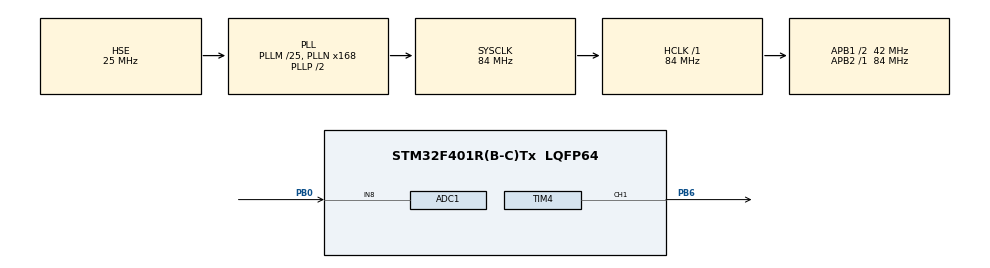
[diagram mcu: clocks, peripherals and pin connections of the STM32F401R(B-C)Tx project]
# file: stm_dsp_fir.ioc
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ADC1.Channel-4\#ChannelRegularConversion=ADC_CHANNEL_8
ADC1.ContinuousConvMode=DISABLE
ADC1.ExternalTrigConv=ADC_EXTERNALTRIGCONV_T2_TRGO
ADC1.NbrOfConversion=1
ADC1.NbrOfConversionFlag=1
ADC1.Rank-4\#ChannelRegularConversion=1
ADC1.Resolution=ADC_RESOLUTION_8B
ADC1.SamplingTime-4\#ChannelRegularConversion=ADC_SAMPLETIME_3CYCLES
ADC1.master=1
Mcu.Family=STM32F4
Mcu.Name=STM32F401R(B-C)Tx
Mcu.Package=LQFP64
NVIC.ADC_IRQn=true\:0\:0\:false\:false\:true\:true\:true\:true
NVIC.PriorityGroup=NVIC_PRIORITYGROUP_4
NVIC.TIM3_IRQn=true\:0\:0\:false\:false\:true\:true\:true\:true
PB0.Signal=ADCx_IN8
PB6.Signal=S_TIM4_CH1
PH0\ -\ OSC_IN.Mode=HSE-External-Oscillator
PH0\ -\ OSC_IN.Signal=RCC_OSC_IN
PH1\ -\ OSC_OUT.Mode=HSE-External-Oscillator
PH1\ -\ OSC_OUT.Signal=RCC_OSC_OUT
ProjectManager.HeapSize=0x200
ProjectManager.StackSize=0x400
ProjectManager.TargetToolchain=STM32CubeIDE
RCC.48MHZClocksFreq_Value=42000000
RCC.AHBFreq_Value=84000000
RCC.APB1CLKDivider=RCC_HCLK_DIV2
RCC.APB1Freq_Value=42000000
RCC.APB1TimFreq_Value=84000000
RCC.APB2Freq_Value=84000000
RCC.APB2TimFreq_Value=84000000
RCC.CortexFreq_Value=84000000
RCC.HCLKFreq_Value=84000000
RCC.HSE_VALUE=25000000
RCC.HSI_VALUE=16000000
RCC.LSE_VALUE=32768
RCC.PLLM=25
RCC.PLLN=168
RCC.PLLSourceVirtual=RCC_PLLSOURCE_HSE
RCC.SYSCLKFreq_VALUE=84000000
RCC.SYSCLKSource=RCC_SYSCLKSOURCE_PLLCLK
RCC.VCOOutputFreq_Value=168000000
SH.ADCx_IN8.0=ADC1_IN8,IN8
SH.S_TIM4_CH1.0=TIM4_CH1,PWM Generation1 CH1
TIM2.AutoReloadPreload=TIM_AUTORELOAD_PRELOAD_ENABLE
TIM2.Period=83999
TIM2.TIM_MasterOutputTrigger=TIM_TRGO_UPDATE
TIM3.AutoReloadPreload=TIM_AUTORELOAD_PRELOAD_ENABLE
TIM3.Prescaler=0
TIM4.AutoReloadPreload=TIM_AUTORELOAD_PRELOAD_ENABLE
TIM4.Channel-PWM\ Generation1\ CH1=TIM_CHANNEL_1
TIM4.Prescaler=0
VP_TIM2_VS_ClockSourceINT.Mode=Internal
VP_TIM3_VS_ClockSourceINT.Mode=Internal
VP_TIM4_VS_ClockSourceINT.Mode=Internal
board=custom

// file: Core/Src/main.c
/* USER CODE BEGIN Header */
/**
  ******************************************************************************
  * @file           : main.c
  * @brief          : Main program body
  ******************************************************************************
  * @attention
  *
  * Copyright (c) 2026 STMicroelectronics.
  * All rights reserved.
  *
  * This software is licensed under terms that can be found in the LICENSE file
  * in the root directory of this software component.
  * If no LICENSE file comes with this software, it is provided AS-IS.
  *
  ******************************************************************************
  */
/* USER CODE END Header */
#include "main.h"

/* USER CODE BEGIN Includes */
#include "sine_gen.h"
/* USER CODE END Includes */

ADC_HandleTypeDef hadc1;

TIM_HandleTypeDef htim2;
TIM_HandleTypeDef htim3;
TIM_HandleTypeDef htim4;

void SystemClock_Config(void);
static void MX_GPIO_Init(void);
static void MX_ADC1_Init(void);
static void MX_TIM2_Init(void);
static void MX_TIM3_Init(void);
static void MX_TIM4_Init(void);

/* USER CODE BEGIN 0 */

/* PERIPHERALS BREAKDOWN */
// TIMER 2 : 1000hz time base, to trigger ADC conversion
// TIMER 3 : Frequency depends on sine wave/noise frequency (see sine_gen.c). Computes and update signal values for wave generator
// TIMER 4 : As fast as possible with as highest resolution, wave generator PWM
// ADC     : Triggered mode by timer 2 update event, interrupt mode

// Note    : Connect RC low pass filter on TIM4 CH1 to generate fake low pass filter, cutoff frequency >= 800hz

#define N_TAPS  8
#define Q_SCALE 128

#define COEFF_0  0x02  /*    2 -> +0.015625  (float: +0.017406) */
#define COEFF_1  0x08  /*    8 -> +0.062500  (float: +0.061207) */
#define COEFF_2  0x15  /*   21 -> +0.164062  (float: +0.166164) */
#define COEFF_3  0x21  /*   33 -> +0.257812  (float: +0.255222) */
#define COEFF_4  0x21  /*   33 -> +0.257812  (float: +0.255222) */
#define COEFF_5  0x15  /*   21 -> +0.164062  (float: +0.166164) */
#define COEFF_6  0x08  /*    8 -> +0.062500  (float: +0.061207) */
#define COEFF_7  0x02  /*    2 -> +0.015625  (float: +0.017406) */

const int8_t fir_coeffs[N_TAPS] = {
    (int8_t)COEFF_0  /*    1 */,
    (int8_t)COEFF_1  /*    6 */,
    (int8_t)COEFF_2  /*   21 */,
    (int8_t)COEFF_3  /*   36 */,
    (int8_t)COEFF_4  /*   36 */,
    (int8_t)COEFF_5  /*   21 */,
    (int8_t)COEFF_6  /*    6 */,
    (int8_t)COEFF_7  /*    1 */
};

int8_t data_pipeline[N_TAPS];
int32_t output_temp;
int32_t output;

volatile int update_flag;
volatile int8_t AD_RES;

uint32_t adc_raw;

void compute_fir(){
	data_pipeline[0] = AD_RES;

	output_temp =  (int32_t)data_pipeline[0]*(int32_t)fir_coeffs[0];
	output_temp += (int32_t)data_pipeline[1]*(int32_t)fir_coeffs[1];
	output_temp += (int32_t)data_pipeline[2]*(int32_t)fir_coeffs[2];
	output_temp += (int32_t)data_pipeline[3]*(int32_t)fir_coeffs[3];
	output_temp += (int32_t)data_pipeline[4]*(int32_t)fir_coeffs[4];
	output_temp += (int32_t)data_pipeline[5]*(int32_t)fir_coeffs[5];
	output_temp += (int32_t)data_pipeline[6]*(int32_t)fir_coeffs[6];
	output_temp += (int32_t)data_pipeline[7]*(int32_t)fir_coeffs[7];

	output_temp = output_temp >> 7;
	if (output_temp > 127) output_temp = 127;
	if (output_temp < -128) output_temp = -128;

	output = output_temp;

	data_pipeline[7] = data_pipeline[6];
	data_pipeline[6] = data_pipeline[5];
	data_pipeline[5] = data_pipeline[4];
	data_pipeline[4] = data_pipeline[3];
	data_pipeline[3] = data_pipeline[2];
	data_pipeline[2] = data_pipeline[1];
	data_pipeline[1] = data_pipeline[0];
}

void HAL_ADC_ConvCpltCallback(ADC_HandleTypeDef* hadc)
{
    AD_RES = (int8_t)(((int16_t)HAL_ADC_GetValue(&hadc1)) - Q_SCALE);

//    AD_RES = HAL_ADC_GetValue(&hadc1);
//    adc_raw = HAL_ADC_GetValue(&hadc1);

    update_flag = 1;

}
/* USER CODE END 0 */

int main(void)
{

  /* MCU Configuration--------------------------------------------------------*/

  /* Reset of all peripherals, Initializes the Flash interface and the Systick. */
  HAL_Init();

  /* Configure the system clock */
  SystemClock_Config();

  /* Initialize all configured peripherals */
  MX_GPIO_Init();
  MX_ADC1_Init();
  MX_TIM2_Init();
  MX_TIM3_Init();
  MX_TIM4_Init();
  /* USER CODE BEGIN 2 */

  HAL_TIM_Base_Start(&htim2);
  HAL_ADC_Start_IT(&hadc1);
  update_flag = 0;

  sine_gen_init(&htim3, &htim4);
  /* USER CODE END 2 */

  /* Infinite loop */
  /* USER CODE BEGIN WHILE */
  while (1)
  {
	  if(update_flag){
		  update_flag = 0;
		  compute_fir();
	  }
    /* USER CODE END WHILE */

  }
}

void SystemClock_Config(void)
{
  RCC_OscInitTypeDef RCC_OscInitStruct = {0};
  RCC_ClkInitTypeDef RCC_ClkInitStruct = {0};

  /** Configure the main internal regulator output voltage
  */
  __HAL_RCC_PWR_CLK_ENABLE();
  __HAL_PWR_VOLTAGESCALING_CONFIG(PWR_REGULATOR_VOLTAGE_SCALE2);

  /** Initializes the RCC Oscillators according to the specified parameters
  * in the RCC_OscInitTypeDef structure.
  */
  RCC_OscInitStruct.OscillatorType = RCC_OSCILLATORTYPE_HSE;
  RCC_OscInitStruct.HSEState = RCC_HSE_ON;
  RCC_OscInitStruct.PLL.PLLState = RCC_PLL_ON;
  RCC_OscInitStruct.PLL.PLLSource = RCC_PLLSOURCE_HSE;
  RCC_OscInitStruct.PLL.PLLM = 25;
  RCC_OscInitStruct.PLL.PLLN = 168;
  RCC_OscInitStruct.PLL.PLLP = RCC_PLLP_DIV2;
  RCC_OscInitStruct.PLL.PLLQ = 4;
  if (HAL_RCC_OscConfig(&RCC_OscInitStruct) != HAL_OK)
  {
    Error_Handler();
  }

  /** Initializes the CPU, AHB and APB buses clocks
  */
  RCC_ClkInitStruct.ClockType = RCC_CLOCKTYPE_HCLK|RCC_CLOCKTYPE_SYSCLK
                              |RCC_CLOCKTYPE_PCLK1|RCC_CLOCKTYPE_PCLK2;
  RCC_ClkInitStruct.SYSCLKSource = RCC_SYSCLKSOURCE_PLLCLK;
  RCC_ClkInitStruct.AHBCLKDivider = RCC_SYSCLK_DIV1;
  RCC_ClkInitStruct.APB1CLKDivider = RCC_HCLK_DIV2;
  RCC_ClkInitStruct.APB2CLKDivider = RCC_HCLK_DIV1;

  if (HAL_RCC_ClockConfig(&RCC_ClkInitStruct, FLASH_LATENCY_2) != HAL_OK)
  {
    Error_Handler();
  }
}

static void MX_ADC1_Init(void)
{

  ADC_ChannelConfTypeDef sConfig = {0};

  /** Configure the global features of the ADC (Clock, Resolution, Data Alignment and number of conversion)
  */
  hadc1.Instance = ADC1;
  hadc1.Init.ClockPrescaler = ADC_CLOCK_SYNC_PCLK_DIV4;
  hadc1.Init.Resolution = ADC_RESOLUTION_8B;
  hadc1.Init.ScanConvMode = DISABLE;
  hadc1.Init.ContinuousConvMode = DISABLE;
  hadc1.Init.DiscontinuousConvMode = DISABLE;
  hadc1.Init.ExternalTrigConvEdge = ADC_EXTERNALTRIGCONVEDGE_RISING;
  hadc1.Init.ExternalTrigConv = ADC_EXTERNALTRIGCONV_T2_TRGO;
  hadc1.Init.DataAlign = ADC_DATAALIGN_RIGHT;
  hadc1.Init.NbrOfConversion = 1;
  hadc1.Init.DMAContinuousRequests = DISABLE;
  hadc1.Init.EOCSelection = ADC_EOC_SINGLE_CONV;
  if (HAL_ADC_Init(&hadc1) != HAL_OK)
  {
    Error_Handler();
  }

  /** Configure for the selected ADC regular channel its corresponding rank in the sequencer and its sample time.
  */
  sConfig.Channel = ADC_CHANNEL_8;
  sConfig.Rank = 1;
  sConfig.SamplingTime = ADC_SAMPLETIME_3CYCLES;
  if (HAL_ADC_ConfigChannel(&hadc1, &sConfig) != HAL_OK)
  {
    Error_Handler();
  }

}

static void MX_TIM2_Init(void)
{

  TIM_ClockConfigTypeDef sClockSourceConfig = {0};
  TIM_MasterConfigTypeDef sMasterConfig = {0};

  htim2.Instance = TIM2;
  htim2.Init.Prescaler = 0;
  htim2.Init.CounterMode = TIM_COUNTERMODE_UP;
  htim2.Init.Period = 83999;
  htim2.Init.ClockDivision = TIM_CLOCKDIVISION_DIV1;
  htim2.Init.AutoReloadPreload = TIM_AUTORELOAD_PRELOAD_ENABLE;
  if (HAL_TIM_Base_Init(&htim2) != HAL_OK)
  {
    Error_Handler();
  }
  sClockSourceConfig.ClockSource = TIM_CLOCKSOURCE_INTERNAL;
  if (HAL_TIM_ConfigClockSource(&htim2, &sClockSourceConfig) != HAL_OK)
  {
    Error_Handler();
  }
  sMasterConfig.MasterOutputTrigger = TIM_TRGO_UPDATE;
  sMasterConfig.MasterSlaveMode = TIM_MASTERSLAVEMODE_DISABLE;
  if (HAL_TIMEx_MasterConfigSynchronization(&htim2, &sMasterConfig) != HAL_OK)
  {
    Error_Handler();
  }

}

static void MX_TIM3_Init(void)
{

  TIM_ClockConfigTypeDef sClockSourceConfig = {0};
  TIM_MasterConfigTypeDef sMasterConfig = {0};

  htim3.Instance = TIM3;
  htim3.Init.Prescaler = 0;
  htim3.Init.CounterMode = TIM_COUNTERMODE_UP;
  htim3.Init.Period = 65535;
  htim3.Init.ClockDivision = TIM_CLOCKDIVISION_DIV1;
  htim3.Init.AutoReloadPreload = TIM_AUTORELOAD_PRELOAD_ENABLE;
  if (HAL_TIM_Base_Init(&htim3) != HAL_OK)
  {
    Error_Handler();
  }
  sClockSourceConfig.ClockSource = TIM_CLOCKSOURCE_INTERNAL;
  if (HAL_TIM_ConfigClockSource(&htim3, &sClockSourceConfig) != HAL_OK)
  {
    Error_Handler();
  }
  sMasterConfig.MasterOutputTrigger = TIM_TRGO_RESET;
  sMasterConfig.MasterSlaveMode = TIM_MASTERSLAVEMODE_DISABLE;
  if (HAL_TIMEx_MasterConfigSynchronization(&htim3, &sMasterConfig) != HAL_OK)
  {
    Error_Handler();
  }

}

static void MX_TIM4_Init(void)
{

  TIM_ClockConfigTypeDef sClockSourceConfig = {0};
  TIM_MasterConfigTypeDef sMasterConfig = {0};
  TIM_OC_InitTypeDef sConfigOC = {0};

  htim4.Instance = TIM4;
  htim4.Init.Prescaler = 0;
  htim4.Init.CounterMode = TIM_COUNTERMODE_UP;
  htim4.Init.Period = 65535;
  htim4.Init.ClockDivision = TIM_CLOCKDIVISION_DIV1;
  htim4.Init.AutoReloadPreload = TIM_AUTORELOAD_PRELOAD_ENABLE;
  if (HAL_TIM_Base_Init(&htim4) != HAL_OK)
  {
    Error_Handler();
  }
  sClockSourceConfig.ClockSource = TIM_CLOCKSOURCE_INTERNAL;
  if (HAL_TIM_ConfigClockSource(&htim4, &sClockSourceConfig) != HAL_OK)
  {
    Error_Handler();
  }
  if (HAL_TIM_PWM_Init(&htim4) != HAL_OK)
  {
    Error_Handler();
  }
  sMasterConfig.MasterOutputTrigger = TIM_TRGO_RESET;
  sMasterConfig.MasterSlaveMode = TIM_MASTERSLAVEMODE_DISABLE;
  if (HAL_TIMEx_MasterConfigSynchronization(&htim4, &sMasterConfig) != HAL_OK)
  {
    Error_Handler();
  }
  sConfigOC.OCMode = TIM_OCMODE_PWM1;
  sConfigOC.Pulse = 0;
  sConfigOC.OCPolarity = TIM_OCPOLARITY_HIGH;
  sConfigOC.OCFastMode = TIM_OCFAST_DISABLE;
  if (HAL_TIM_PWM_ConfigChannel(&htim4, &sConfigOC, TIM_CHANNEL_1) != HAL_OK)
  {
    Error_Handler();
  }
  HAL_TIM_MspPostInit(&htim4);

}

static void MX_GPIO_Init(void)
{

  /* GPIO Ports Clock Enable */
  __HAL_RCC_GPIOH_CLK_ENABLE();
  __HAL_RCC_GPIOB_CLK_ENABLE();

}

void Error_Handler(void)
{
  __disable_irq();
  while (1)
  {
  }
}
